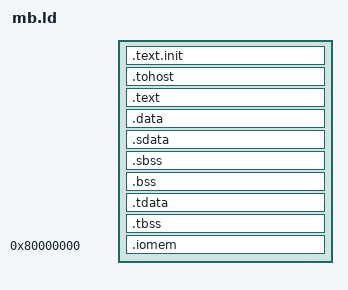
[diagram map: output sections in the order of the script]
/*-----------------------------------------------------------------------------
//  Copyright (c) 2017, Xilinx, Inc.
//  All rights reserved.
//
//  Redistribution and use in source and binary forms, with or without
//  modification, are permitted provided that the following conditions are met:
//
//  1.  Redistributions of source code must retain the above copyright notice,
//     this list of conditions and the following disclaimer.
//
//  2.  Redistributions in binary form must reproduce the above copyright
//      notice, this list of conditions and the following disclaimer in the
//      documentation and/or other materials provided with the distribution.
//
//  3.  Neither the name of the copyright holder nor the names of its
//      contributors may be used to endorse or promote products derived from
//      this software without specific prior written permission.
//
//  THIS SOFTWARE IS PROVIDED BY THE COPYRIGHT HOLDERS AND CONTRIBUTORS "AS IS"
//  AND ANY EXPRESS OR IMPLIED WARRANTIES, INCLUDING, BUT NOT LIMITED TO,
//  THE IMPLIED WARRANTIES OF MERCHANTABILITY AND FITNESS FOR A PARTICULAR
//  PURPOSE ARE DISCLAIMED. IN NO EVENT SHALL THE COPYRIGHT HOLDER OR
//  CONTRIBUTORS BE LIABLE FOR ANY DIRECT, INDIRECT, INCIDENTAL, SPECIAL,
//  EXEMPLARY, OR CONSEQUENTIAL DAMAGES (INCLUDING, BUT NOT LIMITED TO,
//  PROCUREMENT OF SUBSTITUTE GOODS OR SERVICES; LOSS OF USE, DATA, OR PROFITS;
//  OR BUSINESS INTERRUPTION). HOWEVER CAUSED AND ON ANY THEORY OF LIABILITY,
//  WHETHER IN CONTRACT, STRICT LIABILITY, OR TORT (INCLUDING NEGLIGENCE OR
//  OTHERWISE) ARISING IN ANY WAY OUT OF THE USE OF THIS SOFTWARE, EVEN IF
//  ADVISED OF THE POSSIBILITY OF SUCH DAMAGE.
//
-----------------------------------------------------------------------------*/

ENTRY(_start)

/*----------------------------------------------------------------------*/
/* Sections                                                             */
/*----------------------------------------------------------------------*/

SECTIONS
{

  /* text: test code section */
  .text.init : { *(.text.init) }

  . = ALIGN(0x1000);
  .tohost : { *(.tohost) }

  .text : { *(.text) }

  /* data segment */
  .data : { *(.data) }

  .sdata : {
    __global_pointer$ = . + 0x800;
    *(.srodata.cst16) *(.srodata.cst8) *(.srodata.cst4) *(.srodata.cst2) *(.srodata*)
    *(.sdata .sdata.* .gnu.linkonce.s.*)
  }

  /* bss segment */
  .sbss : {
    *(.sbss .sbss.* .gnu.linkonce.sb.*)
    *(.scommon)
  }
  .bss : { *(.bss) }

  /* thread-local data segment */
  .tdata :
  {
    _tls_data = .;
    *(.tdata.begin)
    *(.tdata)
    *(.tdata.end)
  }
  .tbss :
  {
    *(.tbss)
    *(.tbss.end)
  }

  /* End of uninitalized data segement */
  _end = .;
  . = 0x80000000 ;
  .iomem : { *(.iomem) }
}

